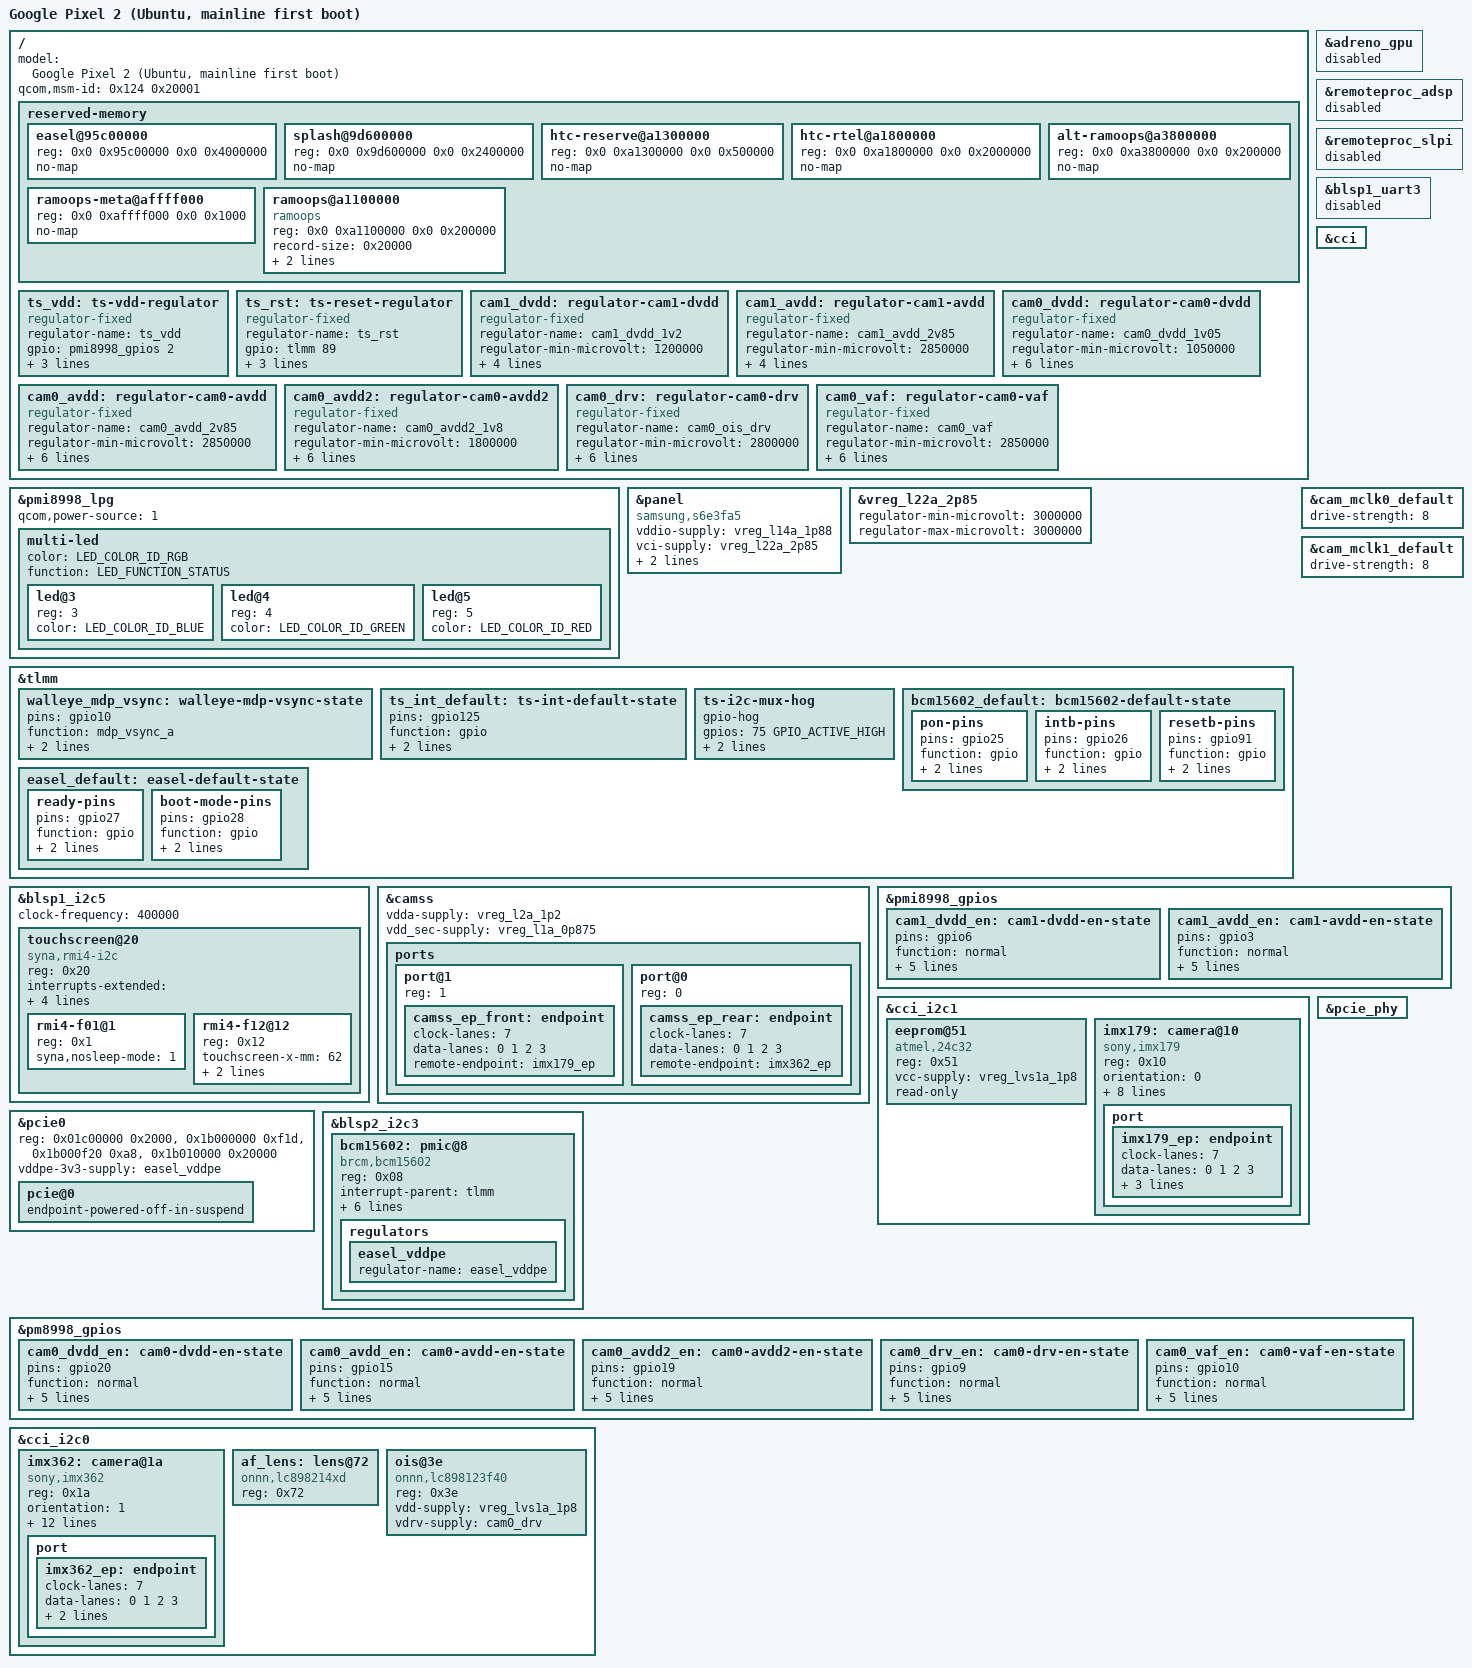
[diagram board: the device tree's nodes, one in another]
// SPDX-License-Identifier: GPL-2.0-only
/*
 * Pixel 2 (walleye), Ubuntu port, mainline FIRST-BOOT device tree (P8.3).
 *
 * Porthole's walleye.dts (never run on a walleye) plus: everything disabled
 * except what a headless boot needs (UFS, USB gadget, regulators, pinctrl,
 * clocks, UART, power key). Re-enable one block at a time:
 *  - mdss: enabled 2026-11-17 with our S6E3FA5 panel driver
 *    (kernel/mainline/patches/0002-*); panel + touch overrides below.
 *  - gpu: not needed for the console.
 *  - mss/wifi: enabled 2026-11-17 (Porthole's wahoo carveouts: 120 MiB mpss,
 *    fixed MSA). Needs rmtfs, tqftpserv, diag-router + firmware in
 *    /lib/firmware/qcom/msm8998/wahoo (scripts/stage-mainline-wifi.sh).
 *  - adsp/slpi: not needed headless.
 *  - charger/fg: enabled (2026-11-17); walleye.dts values (4.4 V, 2700 mAh)
 *    match HTC's downstream batterydata-walleye.
 *  - blsp1_uart3: Bluetooth (needs the wifi/modem side).
 */

#include "msm8998-google-walleye.dts"
#include "wahoo-dtbo-sink.dtsi"
#include <dt-bindings/leds/common.h>
#include <dt-bindings/gpio/gpio.h>
#include <dt-bindings/interrupt-controller/irq.h>

/ {
	model = "Google Pixel 2 (Ubuntu, mainline first boot)";
	/* Same as the factory DTB (MSM8998 v2.1); msm8998.dtsi has <0x124 0x0>. */
	qcom,msm-id = <0x124 0x20001>;
};

&adreno_gpu { status = "disabled"; };
&remoteproc_adsp { status = "disabled"; };
&remoteproc_slpi { status = "disabled"; };
&blsp1_uart3 { status = "disabled"; };

/*
 * Test boot 2 reset ~4 s after the bootloader let go (no USB). Reserve
 * everything the stock walleye layout (factory DTB + dtbo idx 3) reserves
 * that Porthole's taimen-derived map doesn't: memory still owned by
 * firmware/coprocessors would explain an instant reset.
 */
/ {
	reserved-memory {
		easel@95c00000 {	/* Pixel Visual Core (stock: easel_mem) */
			reg = <0x0 0x95c00000 0x0 0x4000000>;
			no-map;
		};
		splash@9d600000 {	/* bootloader splash framebuffer */
			reg = <0x0 0x9d600000 0x0 0x2400000>;
			no-map;
		};
		htc-reserve@a1300000 {
			reg = <0x0 0xa1300000 0x0 0x500000>;
			no-map;
		};
		htc-rtel@a1800000 {
			reg = <0x0 0xa1800000 0x0 0x2000000>;
			no-map;
		};
		alt-ramoops@a3800000 {
			reg = <0x0 0xa3800000 0x0 0x200000>;
			no-map;
		};
		ramoops-meta@affff000 {
			reg = <0x0 0xaffff000 0x0 0x1000>;
			no-map;
		};
	};
};

/*
 * ramoops on the stock region with the stock layout, so the downstream
 * kernel (booted after a mainline crash) can show the mainline log in
 * /sys/fs/pstore.
 */
/delete-node/ &ramoops;
/ {
	reserved-memory {
		ramoops@a1100000 {
			compatible = "ramoops";
			reg = <0x0 0xa1100000 0x0 0x200000>;
			record-size = <0x20000>;
			console-size = <0x100000>;
			pmsg-size = <0x80000>;
		};
	};
};

/* RGB notification LED: PMI8998 LPG channels 3/4/5 = blue/green/red (as on
 * the msm8998 Sony and sdm845 OnePlus boards; downstream: RGB @0xd000). */
&pmi8998_lpg {
	status = "okay";
	qcom,power-source = <1>;

	multi-led {
		color = <LED_COLOR_ID_RGB>;
		function = LED_FUNCTION_STATUS;
		#address-cells = <1>;
		#size-cells = <0>;

		led@3 {
			reg = <3>;
			color = <LED_COLOR_ID_BLUE>;
		};
		led@4 {
			reg = <4>;
			color = <LED_COLOR_ID_GREEN>;
		};
		led@5 {
			reg = <5>;
			color = <LED_COLOR_ID_RED>;
		};
	};
};

/*
 * Display: Samsung S6E3FA5 1080x1920 command mode OLED. The wahoo dtsi's
 * panel node is taimen's (LG SW43402, its own fixed LDOs, TE on gpio11,
 * LAB/IBB rails). Walleye's vendor DT (msm8998-htc_muskie.dtsi,
 * dsi-panel-walleye-s6e3fa5.dtsi): reset gpio94, TE gpio10, vddio = l14
 * (1.8 V), vci = l22 (3.0 V), no LAB/IBB.
 */
&panel {
	compatible = "samsung,s6e3fa5";
	vddio-supply = <&vreg_l14a_1p88>;
	vci-supply = <&vreg_l22a_2p85>;
	/delete-property/ vpnl-supply;
	/delete-property/ lab-supply;
	/delete-property/ ibb-supply;
	disp-te-gpios = <&tlmm 10 GPIO_ACTIVE_LOW>;
	pinctrl-names = "default";
	pinctrl-0 = <&panel_reset_n &walleye_mdp_vsync>;
};

/* Vendor: vci 3.0 V (the wahoo dtsi pins l22 at taimen's 2.864 V). */
&vreg_l22a_2p85 {
	regulator-min-microvolt = <3000000>;
	regulator-max-microvolt = <3000000>;
};

/*
 * Touch: Synaptics RMI4 (vendor synaptics_dsx@20 on i2c_5 = BLSP1 QUP5),
 * msm8998-touch-mw-common.dtsi + msm8998-touch-walleye-xd.dtsi: irq gpio125
 * (low), reset gpio89 (active low), power switch pmi8998 GPIO2 (high = on),
 * gpio75 = I2C mux (0 = AP, 1 = SLPI sensor hub). The vendor also keeps
 * pm8998 l28 at 3.3 V always-on for touch (msm8998-touch-mw-common.dtsi);
 * without it nothing answers on the bus. Chain: l28 -> ts_vdd -> ts_rst.
 */
/*
 * l28 stays at the wahoo dtsi's 3.008 V. The vendor runs it at 3.3 V, but on
 * mainline 3.3 V froze every boot that bound the USB gadget early (tests
 * 25-30: no USB, no watchdog; l28, l20 (UFS) and l24 (USB PHY) share BOB,
 * set to 3.312-3.6 V here). At 3.008 V the chip answers at 0x20 (test 31).
 */

/ {
	ts_vdd: ts-vdd-regulator {
		compatible = "regulator-fixed";
		regulator-name = "ts_vdd";
		gpio = <&pmi8998_gpios 2 GPIO_ACTIVE_HIGH>;
		enable-active-high;
		vin-supply = <&vreg_l28_3p0>;
		startup-delay-us = <20000>;
	};

	/*
	 * rmi4_i2c has no reset GPIO. Model the reset line as a regulator fed by
	 * ts_vdd: enabling it powers the chip first, then releases reset
	 * (vendor: reset-active-ms 1, reset-delay-ms 20; we wait 100 ms).
	 */
	ts_rst: ts-reset-regulator {
		compatible = "regulator-fixed";
		regulator-name = "ts_rst";
		gpio = <&tlmm 89 GPIO_ACTIVE_HIGH>;
		enable-active-high;
		vin-supply = <&ts_vdd>;
		startup-delay-us = <100000>;
	};
};

&tlmm {
	walleye_mdp_vsync: walleye-mdp-vsync-state {
		pins = "gpio10";
		function = "mdp_vsync_a";
		drive-strength = <2>;
		bias-pull-down;
	};

	ts_int_default: ts-int-default-state {
		pins = "gpio125";
		function = "gpio";
		drive-strength = <2>;
		bias-pull-up;
	};

	ts-i2c-mux-hog {
		gpio-hog;
		gpios = <75 GPIO_ACTIVE_HIGH>;
		output-low;		/* touch I2C to the AP */
		line-name = "ts-i2c-mux";
	};
};

&blsp1_i2c5 {
	status = "okay";
	clock-frequency = <400000>;

	touchscreen@20 {
		compatible = "syna,rmi4-i2c";
		reg = <0x20>;
		#address-cells = <1>;
		#size-cells = <0>;

		interrupts-extended = <&tlmm 125 IRQ_TYPE_LEVEL_LOW>;
		vdd-supply = <&ts_rst>;

		pinctrl-names = "default";
		pinctrl-0 = <&ts_int_default>;

		syna,startup-delay-ms = <100>;

		rmi4-f01@1 {
			reg = <0x1>;
			syna,nosleep-mode = <1>;
		};

		rmi4-f12@12 {
			reg = <0x12>;
			touchscreen-x-mm = <62>;
			touchscreen-y-mm = <110>;
			syna,sensor-type = <1>;
		};
	};
};

/*
 * ---- Camera (P8.5), staged as in docs/camera-walleye.md --------------------
 * M1: CCI only (pins as in msm8998.dtsi match walleye: gpio17-20, 2 mA).
 *     master 0 = rear, master 1 = front. Sensors stay unpowered.
 * M2: CAMSS, no ports yet. PHY rails as taimen: l2 1.2 V, l1 0.88 V (both
 *     already on for DSI/UFS). MCLK pads at 8 mA on walleye (HTC), not 2 mA.
 */
&cci {
	status = "okay";
};

&camss {
	status = "okay";
	vdda-supply = <&vreg_l2a_1p2>;
	vdd_sec-supply = <&vreg_l1a_0p875>;
};

&cam_mclk0_default {
	drive-strength = <8>;
};

&cam_mclk1_default {
	drive-strength = <8>;
};

/* Camera M4 before M3 (Easel): the sensor probe (chip ID over CCI) needs
 * no Easel; only streaming does (imx179.c easel_mipi_set_rate/kick). */
/* =====================================================================
 * CAMERA M4 -- front sensor IMX179 + its EEPROM.
 * Rails are PMIC-GPIO-switched (1-based numbering, as TDTS:977-983).
 * Enables are active-high: the vendor lib drives them HIGH to power up
 * (VEND libmmcamera_imx179.so @0x7f0/@0x800, config 2 = GPIO_OUT_HIGH).
 * The vendor DTBO only sets their BOOT level high (invert=1, DTBO:4624,
 * :4634); here they start low -- see risks.
 * ===================================================================== */
/ {
	cam1_dvdd: regulator-cam1-dvdd {
		compatible = "regulator-fixed";
		regulator-name = "cam1_dvdd_1v2";	/* DTBO:4532 */
		regulator-min-microvolt = <1200000>;
		regulator-max-microvolt = <1200000>;
		gpio = <&pmi8998_gpios 6 GPIO_ACTIVE_HIGH>;	/* DTBO:4528 */
		enable-active-high;
		pinctrl-names = "default";
		pinctrl-0 = <&cam1_dvdd_en>;
	};

	cam1_avdd: regulator-cam1-avdd {
		compatible = "regulator-fixed";
		/* 2.85 V per walleye (DTBO:4532, XA:426); taimen said 2.7 V.
		 * Informational only: imx179.c never sets a voltage. */
		regulator-name = "cam1_avdd_2v85";
		regulator-min-microvolt = <2850000>;
		regulator-max-microvolt = <2850000>;
		gpio = <&pmi8998_gpios 3 GPIO_ACTIVE_HIGH>;	/* DTBO:4530 */
		enable-active-high;
		pinctrl-names = "default";
		pinctrl-0 = <&cam1_avdd_en>;
	};
};

&pmi8998_gpios {
	/* DTBO:4629-4636 gpio@c500: mode out, no pull, vin-sel 0 */
	cam1_dvdd_en: cam1-dvdd-en-state {
		pins = "gpio6";
		function = "normal";
		bias-disable;
		drive-push-pull;
		output-low;
		power-source = <0>;
		qcom,drive-strength = <1>;	/* UNCONFIRMED: copied from TDTS */
	};

	/* DTBO:4619-4626 gpio@c200: same */
	cam1_avdd_en: cam1-avdd-en-state {
		pins = "gpio3";
		function = "normal";
		bias-disable;
		drive-push-pull;
		output-low;
		power-source = <0>;
		qcom,drive-strength = <1>;	/* UNCONFIRMED: copied from TDTS */
	};
};

&camss {
	ports {
		/* CSIPHY1/CSID1 (DTBO:4524-4525), 4 lanes (camera_config.xml:126) */
		port@1 {
			reg = <1>;
			camss_ep_front: endpoint {
				clock-lanes = <7>;
				data-lanes = <0 1 2 3>;
				remote-endpoint = <&imx179_ep>;
			};
		};
	};
};

&cci_i2c1 {
	/* VEND libmmcamera_sony_imx179_eeprom.so @0x17b4: 0xA2 -> 0x51,
	 * 16-bit addressed, 0x758 bytes. Same as taimen (TDTS:1229). */
	eeprom@51 {
		compatible = "atmel,24c32";
		reg = <0x51>;
		vcc-supply = <&vreg_lvs1a_1p8>;
		read-only;
	};

	/* VEND libmmcamera_imx179.so @0x7c8: 0x20 -> 0x10 */
	imx179: camera@10 {
		compatible = "sony,imx179";
		reg = <0x10>;

		orientation = <0>;
		/*
		 * UNCONFIRMED. Vendor mount angle is 270 here (DTBO:4526,
		 * camera_config.xml:123) vs 90 on taimen (TCAM:209), whose
		 * owner-verified mainline value is 90 (TDTS:1250-1256). The
		 * module is turned 180 deg relative to taimen, hence 270.
		 * Verify on the live viewfinder (mind the selfie mirror).
		 */
		rotation = <270>;

		clocks = <&mmcc CAMSS_MCLK1_CLK>;	/* no assigned-clocks: TDTS:1270-1278 */
		power-domains = <&mmcc CAMSS_TOP_GDSC>;

		pinctrl-names = "default";
		pinctrl-0 = <&cam_mclk1_default>;

		reset-gpios = <&tlmm 23 GPIO_ACTIVE_LOW>;	/* DTBO:4539 */

		vio-supply = <&vreg_lvs1a_1p8>;			/* DTBO:4529 */
		vdig-supply = <&cam1_dvdd>;
		vana-supply = <&cam1_avdd>;

		port {
			imx179_ep: endpoint {
				clock-lanes = <7>;
				data-lanes = <0 1 2 3>;
				/* same op_pixel_clk table as taimen
				 * (VEND @0xa8be0 / @0xa8ca0) */
				link-frequencies = /bits/ 64 <170000000 270000000 324000000>;
				remote-endpoint = <&camss_ep_front>;
			};
		};
	};
};

/* Camera M3: Easel. bcm15602-easel and easel-mipi are modules (ubuntu.config),
 * so PCIe waits for easel_vddpe until bcm15602-easel is loaded. */
/* =====================================================================
 * CAMERA M3 -- Easel MIPI bridge (needed for any frame; CCI chip-ID reads
 * work without it). Copied from TDTS:711-878; every walleye value
 * confirmed against DTBO:3875-4093 / HEASEL. Easel enumerates on this
 * phone under 4.4 (DMESG: 8086:3140, BAR 4K/8M/4M).
 * RAM-BOOT ONLY: a mis-sized BAR window hung taimen's fabric (TDTS:727-729).
 * ===================================================================== */
&pcie_phy {
	status = "okay";
};

&pcie0 {
	status = "okay";

	/* Same windows as walleye's DTBO fragment@121 (DTBO:3879-3880). */
	reg = <0x01c00000 0x2000>,
	      <0x1b000000 0xf1d>,
	      <0x1b000f20 0xa8>,
	      <0x1b010000 0x20000>;
	reg-names = "parf", "dbi", "elbi", "config";

	ranges = <0x01000000 0x0 0x1b030000 0x1b030000 0x0 0x20000>,
		 <0x02000000 0x0 0x1b100000 0x1b100000 0x0 0xf00000>;

	vddpe-3v3-supply = <&easel_vddpe>;

	pcie@0 {
		endpoint-powered-off-in-suspend;
	};

	/*
	 * NOT EXPRESSIBLE: walleye's vendor PHY sequence ends with an extra
	 * TX_DRV_LVL = 0x2d (DTBO:3881 last triple; HEASEL:106) that
	 * taimen and the SoC table lack. If link training is flaky on
	 * walleye, that is a driver-table change, not a DT one.
	 */
};

&blsp2_i2c3 {	/* downstream i2c_9 (DTBO fixup i2c_9, :5359) */
	status = "okay";

	bcm15602: pmic@8 {	/* DTBO:4020-4030; HEASEL:218-246 */
		compatible = "brcm,bcm15602";
		reg = <0x08>;

		interrupt-parent = <&tlmm>;
		interrupts = <26 IRQ_TYPE_EDGE_FALLING>;
		interrupt-names = "bcm15602_intb";

		pinctrl-names = "default";
		pinctrl-0 = <&bcm15602_default>;

		pon-gpios = <&tlmm 25 GPIO_ACTIVE_HIGH>;
		resetb-gpios = <&tlmm 91 GPIO_ACTIVE_HIGH>;

		/* mnh-sm ref_clk / sleep_clk (DTBO:4085-4087; HEASEL:278-280) */
		clocks = <&rpmcc RPM_SMD_LN_BB_CLK2>,
			 <&rpmcc RPM_SMD_DIV_CLK3>;
		clock-names = "ref", "sleep";

		regulators {
			easel_vddpe: easel_vddpe {
				regulator-name = "easel_vddpe";
			};
		};
	};
};

&tlmm {
	bcm15602_default: bcm15602-default-state {	/* DTBO:3890-3943 */
		pon-pins {
			pins = "gpio25";
			function = "gpio";
			drive-strength = <2>;
			bias-disable;
		};

		intb-pins {
			pins = "gpio26";
			function = "gpio";
			drive-strength = <2>;
			bias-pull-up;
		};

		resetb-pins {
			pins = "gpio91";
			function = "gpio";
			drive-strength = <2>;
			bias-pull-down;
		};
	};

	/* Unreferenced, as on taimen (TDTS:863); DTBO:3946-3976. */
	easel_default: easel-default-state {
		ready-pins {
			pins = "gpio27";
			function = "gpio";
			drive-strength = <2>;
			bias-pull-down;
		};

		boot-mode-pins {
			pins = "gpio28";
			function = "gpio";
			drive-strength = <2>;
			bias-disable;
		};
	};
};

/* =====================================================================
 * CAMERA M5 -- rear sensor IMX362.
 * ===================================================================== */
/ {
	cam0_dvdd: regulator-cam0-dvdd {
		compatible = "regulator-fixed";
		regulator-name = "cam0_dvdd_1v05";		/* DTBO:4494 */
		regulator-min-microvolt = <1050000>;
		regulator-max-microvolt = <1050000>;
		gpio = <&pm8998_gpios 20 GPIO_ACTIVE_HIGH>;	/* DTBO:4492 */
		enable-active-high;
		pinctrl-names = "default";
		pinctrl-0 = <&cam0_dvdd_en>;
	};

	cam0_avdd: regulator-cam0-avdd {
		compatible = "regulator-fixed";
		regulator-name = "cam0_avdd_2v85";		/* DTBO:4494, XA:369 */
		regulator-min-microvolt = <2850000>;
		regulator-max-microvolt = <2850000>;
		gpio = <&pm8998_gpios 15 GPIO_ACTIVE_HIGH>;	/* DTBO:4491 */
		enable-active-high;
		pinctrl-names = "default";
		pinctrl-0 = <&cam0_avdd_en>;
	};

	cam0_avdd2: regulator-cam0-avdd2 {
		compatible = "regulator-fixed";
		regulator-name = "cam0_avdd2_1v8";		/* "CAM1_A1V8", DTBO:4510 */
		regulator-min-microvolt = <1800000>;		/* UNCONFIRMED (name only) */
		regulator-max-microvolt = <1800000>;
		gpio = <&pm8998_gpios 19 GPIO_ACTIVE_HIGH>;	/* DTBO:4501 #6 */
		enable-active-high;
		pinctrl-names = "default";
		pinctrl-0 = <&cam0_avdd2_en>;
	};

	cam0_drv: regulator-cam0-drv {
		compatible = "regulator-fixed";
		regulator-name = "cam0_ois_drv";		/* "CAM1_DRV", DTBO:4510 */
		regulator-min-microvolt = <2800000>;		/* UNCONFIRMED (taimen label) */
		regulator-max-microvolt = <2800000>;
		gpio = <&pm8998_gpios 9 GPIO_ACTIVE_HIGH>;	/* DTBO:4501 #7 */
		enable-active-high;
		pinctrl-names = "default";
		pinctrl-0 = <&cam0_drv_en>;
	};

	cam0_vaf: regulator-cam0-vaf {
		compatible = "regulator-fixed";
		regulator-name = "cam0_vaf";			/* "CAM1_VAF", DTBO:4510 */
		regulator-min-microvolt = <2850000>;		/* UNCONFIRMED (taimen label) */
		regulator-max-microvolt = <2850000>;
		gpio = <&pm8998_gpios 10 GPIO_ACTIVE_HIGH>;	/* DTBO:4501 #5 */
		enable-active-high;
		pinctrl-names = "default";
		pinctrl-0 = <&cam0_vaf_en>;
	};
};

&pm8998_gpios {
	/* WALLEYE DIFFERENCE: vin-sel 1 (DTBO:4605 gpio@d300; XA:504).
	 * taimen uses 0 (TCAM:313, TDTS:1081). */
	cam0_dvdd_en: cam0-dvdd-en-state {
		pins = "gpio20";
		function = "normal";
		bias-disable;
		drive-push-pull;
		output-low;
		power-source = <1>;	/* walleye DTBO vin-sel 1; taimen's 0 changed nothing (tests 39/40) */
		qcom,drive-strength = <1>;	/* UNCONFIRMED: copied from TDTS */
	};

	cam0_avdd_en: cam0-avdd-en-state {	/* DTBO:4582-4589, vin-sel 0 */
		pins = "gpio15";
		function = "normal";
		bias-disable;
		drive-push-pull;
		output-low;
		power-source = <0>;
		qcom,drive-strength = <1>;
	};

	cam0_avdd2_en: cam0-avdd2-en-state {	/* DTBO:4592-4599, vin-sel 0 */
		pins = "gpio19";
		function = "normal";
		bias-disable;
		drive-push-pull;
		output-low;
		power-source = <0>;
		qcom,drive-strength = <1>;
	};

	cam0_drv_en: cam0-drv-en-state {	/* DTBO:4562-4569, vin-sel 0 */
		pins = "gpio9";
		function = "normal";
		bias-disable;
		drive-push-pull;
		output-low;
		power-source = <0>;
		qcom,drive-strength = <1>;
	};

	cam0_vaf_en: cam0-vaf-en-state {	/* DTBO:4572-4579, vin-sel 0 */
		pins = "gpio10";
		function = "normal";
		bias-disable;
		drive-push-pull;
		output-low;
		power-source = <0>;
		qcom,drive-strength = <1>;
	};
};

&camss {
	ports {
		/* CSIPHY0/CSID0 (DTBO:4483-4484), 4 lanes (camera_config.xml:103) */
		port@0 {
			reg = <0>;
			camss_ep_rear: endpoint {
				clock-lanes = <7>;
				data-lanes = <0 1 2 3>;
				remote-endpoint = <&imx362_ep>;
			};
		};
	};
};

&cci_i2c0 {
	/* VEND libmmcamera_imx362.so @0x1080: 0x34 -> 0x1a */
	imx362: camera@1a {
		compatible = "sony,imx362";
		reg = <0x1a>;

		orientation = <1>;
		/*
		 * Vendor mount angle 90 (DTBO:4485, camera_config.xml:100) vs
		 * 270 on taimen (TCAM:155), where mainline uses 90 (TDTS:1168-
		 * 1169), so rotated 180 deg -> 270. CONFIRMED 2026-11-18: with
		 * the phone upright the frame needs 90 deg counter-clockwise
		 * (desk and letter trays upright), as for the front (270).
		 */
		rotation = <270>;

		clocks = <&mmcc CAMSS_MCLK0_CLK>;
		power-domains = <&mmcc CAMSS_TOP_GDSC>;

		pinctrl-names = "default";
		pinctrl-0 = <&cam_mclk0_default>;

		reset-gpios = <&tlmm 24 GPIO_ACTIVE_LOW>;	/* DTBO:4501 #2 */

		vdrv-supply = <&cam0_drv>;
		vaf-supply = <&cam0_vaf>;
		vdig-supply = <&cam0_dvdd>;
		vio-supply = <&vreg_lvs1a_1p8>;			/* DTBO:4490 */
		vana-supply = <&cam0_avdd>;
		vana2-supply = <&cam0_avdd2>;

		port {
			imx362_ep: endpoint {
				clock-lanes = <7>;
				data-lanes = <0 1 2 3>;
				/* op_pixel_clk 548 MHz (VEND @0xa9498) * 10 / 8 */
				link-frequencies = /bits/ 64 <685000000>;
				remote-endpoint = <&camss_ep_rear>;
			};
		};
	};
};

/*
 * Camera M6 (part): AF actuator + OIS on the rear CCI bus (docs/camera-walleye.md).
 * Both answer without MCLK, so they also show whether CCI0 + the rear rails work.
 */
&cci_i2c0 {
	/* VEND libactuator_lc898214xd.so @0x48c: 0xE4 -> 0x72 */
	af_lens: lens@72 {
		compatible = "onnn,lc898214xd";
		reg = <0x72>;
	};

	/* VEND libois_lc898123f40.so @0x43c: 0x7C -> 0x3e. Also holds the
	 * rear calibration (VEND libmmcamera_sony_imx362_eeprom.so @0x3a78). */
	ois@3e {
		compatible = "onnn,lc898123f40";
		reg = <0x3e>;
		vdd-supply = <&vreg_lvs1a_1p8>;
		vdrv-supply = <&cam0_drv>;
	};
};

&imx362 {
	lens-focus = <&af_lens>;
};

/*
 * Rear rails stay on: with them switched by the imx362 driver the sensor never
 * answers its chip-ID read (-110, tests 39/40); with them on from boot it
 * probes, the OIS answers (firmware 0x19) and frames stream (test 41).
 * Unknown which rail/timing the module needs (taimen's driver comment says the
 * OIS only answers once the IMX362 rails are up). Follow-up: find it and let
 * the driver switch them again (idle power).
 */
&cam0_dvdd { regulator-always-on; regulator-boot-on; };
&cam0_avdd { regulator-always-on; regulator-boot-on; };
&cam0_avdd2 { regulator-always-on; regulator-boot-on; };
&cam0_drv { regulator-always-on; regulator-boot-on; };
&cam0_vaf { regulator-always-on; regulator-boot-on; };
